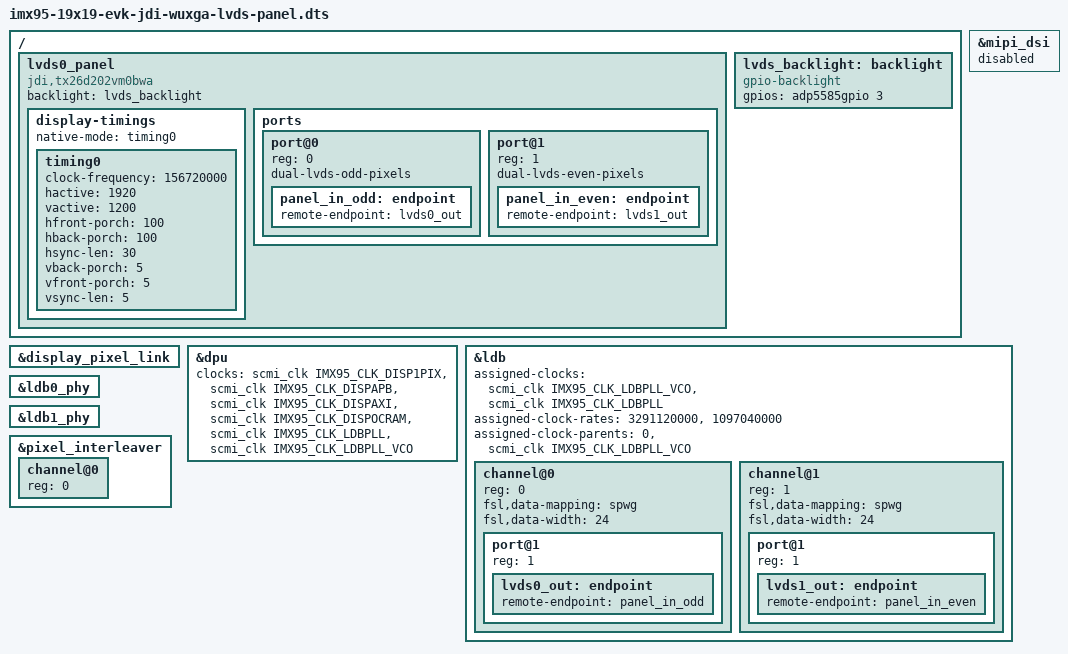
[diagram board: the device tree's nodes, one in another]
// SPDX-License-Identifier: (GPL-2.0+ OR MIT)
/*
 * Copyright 2024 NXP
 */

#include "imx95-19x19-evk.dts"
#include "imx95-19x19-evk-u-boot.dtsi"

/ {
	lvds0_panel {
		compatible = "jdi,tx26d202vm0bwa";
		backlight = <&lvds_backlight>;

		display-timings {
			native-mode = <&timing0>;

			timing0: timing0 {
				clock-frequency = <156720000>;
				hactive = <1920>;
				vactive = <1200>;
				hfront-porch = <100>;
				hback-porch = <100>;
				hsync-len = <30>;
				vback-porch = <5>;
				vfront-porch = <5>;
				vsync-len = <5>;
			};
		};

		ports {
			#address-cells = <1>;
			#size-cells = <0>;

			port@0 {
				reg = <0>;
				dual-lvds-odd-pixels;
				panel_in_odd: endpoint {
					remote-endpoint = <&lvds0_out>;
				};
			};


			port@1 {
				reg = <1>;
				dual-lvds-even-pixels;
				panel_in_even: endpoint {
					remote-endpoint = <&lvds1_out>;
				};
			};
		};
	};

	lvds_backlight: backlight {
		compatible = "gpio-backlight";
		gpios = <&adp5585gpio 3 GPIO_ACTIVE_HIGH>;
	};
};

&display_pixel_link {
	status = "okay";
};

&dpu {
	clocks = <&scmi_clk IMX95_CLK_DISP1PIX>,
				 <&scmi_clk IMX95_CLK_DISPAPB>,
				 <&scmi_clk IMX95_CLK_DISPAXI>,
				 <&scmi_clk IMX95_CLK_DISPOCRAM>,
				 <&scmi_clk IMX95_CLK_LDBPLL>,
				 <&scmi_clk IMX95_CLK_LDBPLL_VCO>;
	status = "okay";
};

&mipi_dsi {
	status = "disabled";
};

&ldb {
	#address-cells = <1>;
	#size-cells = <0>;
	assigned-clocks = <&scmi_clk IMX95_CLK_LDBPLL_VCO>,
			  <&scmi_clk IMX95_CLK_LDBPLL>;
	assigned-clock-rates = <3291120000>, <1097040000>;
	assigned-clock-parents = <0>, <&scmi_clk IMX95_CLK_LDBPLL_VCO>;
	status = "okay";

	channel@0 {
		#address-cells = <1>;
		#size-cells = <0>;
		reg = <0>;
		fsl,data-mapping = "spwg";
		fsl,data-width = <24>;
		status = "okay";

		port@1 {
			reg = <1>;

			lvds0_out: endpoint {
				remote-endpoint = <&panel_in_odd>;
			};
		};
	};

	channel@1 {
		#address-cells = <1>;
		#size-cells = <0>;
		reg = <1>;
		fsl,data-mapping = "spwg";
		fsl,data-width = <24>;
		status = "okay";

		port@1 {
			reg = <1>;

			lvds1_out: endpoint {
				remote-endpoint = <&panel_in_even>;
			};
		};
	};
};

&ldb0_phy {
	status = "okay";
};

&ldb1_phy {
	status = "okay";
};

&pixel_interleaver {
	#address-cells = <1>;
	#size-cells = <0>;
	status = "okay";

	channel@0 {
		reg = <0>;
		status = "okay";
	};
};
